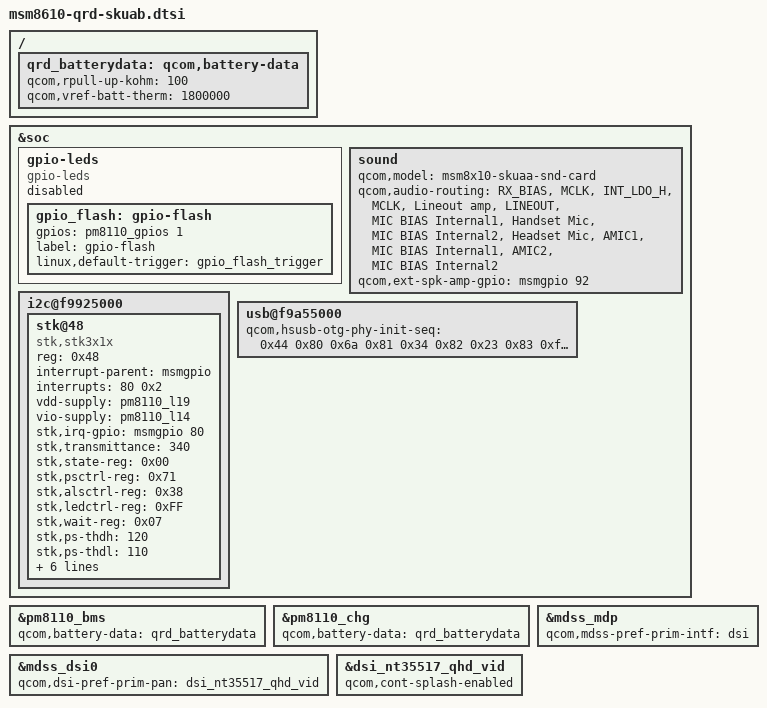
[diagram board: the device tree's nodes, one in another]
/* Copyright (c) 2013, The Linux Foundation. All rights reserved.
 *
 * This program is free software; you can redistribute it and/or modify
 * it under the terms of the GNU General Public License version 2 and
 * only version 2 as published by the Free Software Foundation.
 *
 * This program is distributed in the hope that it will be useful,
 * but WITHOUT ANY WARRANTY; without even the implied warranty of
 * MERCHANTABILITY or FITNESS FOR A PARTICULAR PURPOSE.  See the
 * GNU General Public License for more details.
 */

/include/ "msm8610-qrd.dtsi"

&soc {
	gpio-leds {
		compatible = "gpio-leds";
		status = "disabled";

		gpio_flash: gpio-flash {
			gpios = <&pm8110_gpios 1 0>;
			label = "gpio-flash";
			linux,default-trigger = "gpio_flash_trigger";
		};
	};
    sound {
        qcom,model = "msm8x10-skuaa-snd-card";

        qcom,audio-routing =
            "RX_BIAS", "MCLK",
            "INT_LDO_H", "MCLK",
            "Lineout amp", "LINEOUT",
            "MIC BIAS Internal1", "Handset Mic",
            "MIC BIAS Internal2", "Headset Mic",
            "AMIC1", "MIC BIAS Internal1",
            "AMIC2", "MIC BIAS Internal2";

        qcom,ext-spk-amp-gpio = <&msmgpio 92 0x0>;
    };

    i2c@f9925000 {
		stk@48 {
			compatible = "stk,stk3x1x";
			reg = <0x48>;
			interrupt-parent = <&msmgpio>;
			interrupts = <80 0x2>;
			vdd-supply = <&pm8110_l19>;
			vio-supply = <&pm8110_l14>;
			stk,irq-gpio = <&msmgpio 80 0x02>;
			stk,transmittance = <340>;
			stk,state-reg = <0x00>;
			stk,psctrl-reg = <0x71>;
			stk,alsctrl-reg = <0x38>;
			stk,ledctrl-reg = <0xFF>;
			stk,wait-reg = <0x07>;
			stk,ps-thdh = <120>;
			stk,ps-thdl = <110>;
			stk,als-cmd = <0x41>;
			stk,ps-cmd = <0x21>;
			stk,ps-gain = <0xf>;
			stk,ps-high-thd = <0x78>;
			stk,ps-low-thd = <0x6e>;
			stk,use-fir;
		};
	};

	usb@f9a55000 {
               qcom,hsusb-otg-phy-init-seq =
                       <0x44 0x80 0x6a 0x81 0x34 0x82 0x23 0x83 0xffffffff>;
	};
};

/ {
	qrd_batterydata: qcom,battery-data {
		qcom,rpull-up-kohm = <100>;
		qcom,vref-batt-therm = <1800000>;

		/include/ "batterydata-qrd-4v35-2000mah.dtsi"
	};
};

&pm8110_bms {
	status = "ok";
	qcom,battery-data = <&qrd_batterydata>;
};

&pm8110_chg {
	qcom,battery-data = <&qrd_batterydata>;
};

&mdss_mdp {
	qcom,mdss-pref-prim-intf = "dsi";
};

&mdss_dsi0 {
	qcom,dsi-pref-prim-pan = <&dsi_nt35517_qhd_vid>;
};

&dsi_nt35517_qhd_vid {
	qcom,cont-splash-enabled;
};
